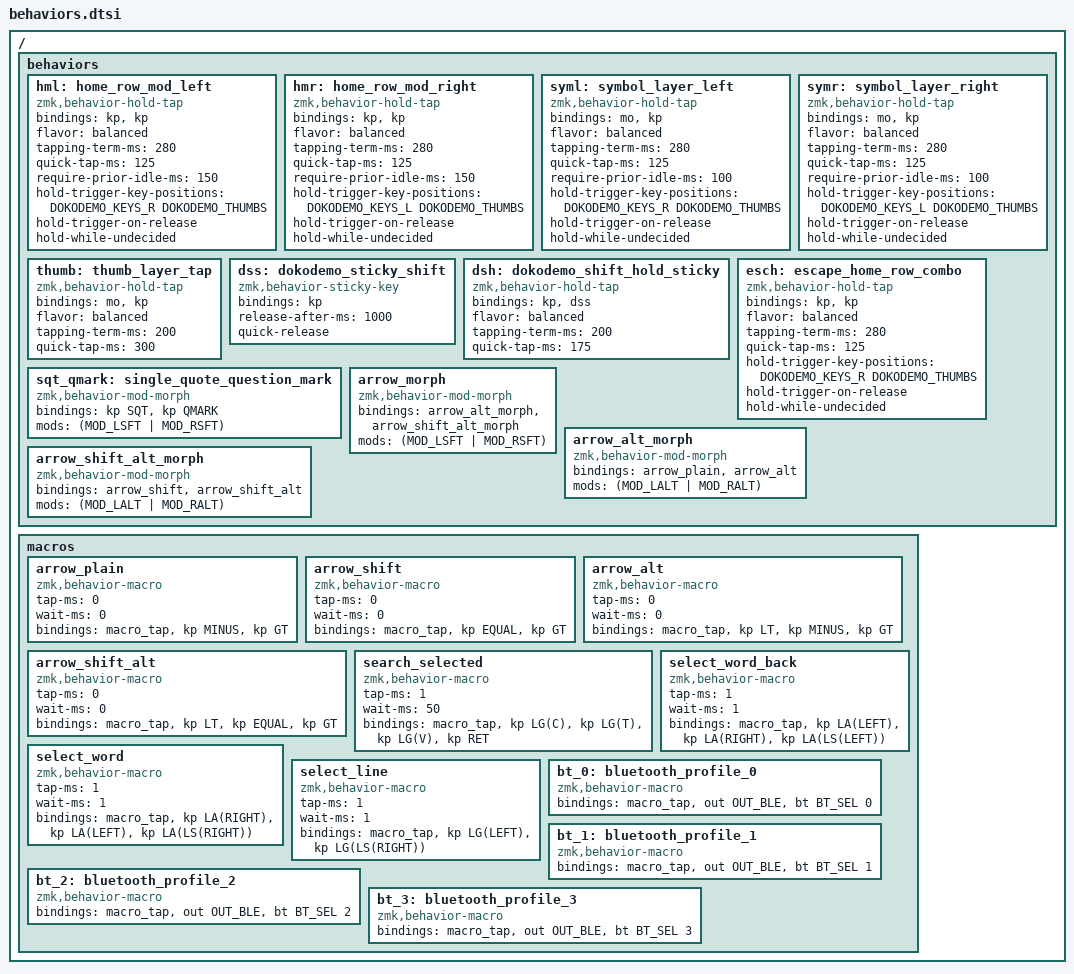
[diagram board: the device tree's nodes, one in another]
#include <behaviors.dtsi>
#include <dt-bindings/zmk/bt.h>
#include <dt-bindings/zmk/keys.h>
#include <dt-bindings/zmk/modifiers.h>
#include <dt-bindings/zmk/outputs.h>

#define DOKODEMO_KEYS_L 0 1 2 3 4 10 11 12 13 14 20 21 22 23 24
#define DOKODEMO_KEYS_R 5 6 7 8 9 15 16 17 18 19 25 26 27 28 29
#define DOKODEMO_THUMBS 30 31 32 33

/ {
    behaviors {
        // Go60-style bilateral home-row mods for the non-index fingers.
        hml: home_row_mod_left {
            compatible = "zmk,behavior-hold-tap";
            #binding-cells = <2>;
            bindings = <&kp>, <&kp>;
            flavor = "balanced";
            tapping-term-ms = <280>;
            quick-tap-ms = <125>;
            require-prior-idle-ms = <150>;
            hold-trigger-key-positions = <DOKODEMO_KEYS_R DOKODEMO_THUMBS>;
            hold-trigger-on-release;
            hold-while-undecided;
        };

        hmr: home_row_mod_right {
            compatible = "zmk,behavior-hold-tap";
            #binding-cells = <2>;
            bindings = <&kp>, <&kp>;
            flavor = "balanced";
            tapping-term-ms = <280>;
            quick-tap-ms = <125>;
            require-prior-idle-ms = <150>;
            hold-trigger-key-positions = <DOKODEMO_KEYS_L DOKODEMO_THUMBS>;
            hold-trigger-on-release;
            hold-while-undecided;
        };

        // The index home keys hold the Symbol layer instead of a modifier.
        syml: symbol_layer_left {
            compatible = "zmk,behavior-hold-tap";
            #binding-cells = <2>;
            bindings = <&mo>, <&kp>;
            flavor = "balanced";
            tapping-term-ms = <280>;
            quick-tap-ms = <125>;
            require-prior-idle-ms = <100>;
            hold-trigger-key-positions = <DOKODEMO_KEYS_R DOKODEMO_THUMBS>;
            hold-trigger-on-release;
            hold-while-undecided;
        };

        symr: symbol_layer_right {
            compatible = "zmk,behavior-hold-tap";
            #binding-cells = <2>;
            bindings = <&mo>, <&kp>;
            flavor = "balanced";
            tapping-term-ms = <280>;
            quick-tap-ms = <125>;
            require-prior-idle-ms = <100>;
            hold-trigger-key-positions = <DOKODEMO_KEYS_L DOKODEMO_THUMBS>;
            hold-trigger-on-release;
            hold-while-undecided;
        };

        // Go60's balanced layer-tap behavior for Backspace/Cursor and Space/Num.
        thumb: thumb_layer_tap {
            compatible = "zmk,behavior-hold-tap";
            #binding-cells = <2>;
            bindings = <&mo>, <&kp>;
            flavor = "balanced";
            tapping-term-ms = <200>;
            quick-tap-ms = <300>;
        };

        // Hold for Shift; tap for one-shot Shift on the next resolved keycode.
        dss: dokodemo_sticky_shift {
            compatible = "zmk,behavior-sticky-key";
            #binding-cells = <1>;
            bindings = <&kp>;
            release-after-ms = <1000>;
            quick-release;
        };

        dsh: dokodemo_shift_hold_sticky {
            compatible = "zmk,behavior-hold-tap";
            #binding-cells = <2>;
            bindings = <&kp>, <&dss>;
            flavor = "balanced";
            tapping-term-ms = <200>;
            quick-tap-ms = <175>;
        };

        // Tap the A+S combo for Escape; hold it with the other hand for Ctrl+Alt.
        esch: escape_home_row_combo {
            compatible = "zmk,behavior-hold-tap";
            #binding-cells = <2>;
            bindings = <&kp>, <&kp>;
            flavor = "balanced";
            tapping-term-ms = <280>;
            quick-tap-ms = <125>;
            hold-trigger-key-positions = <DOKODEMO_KEYS_R DOKODEMO_THUMBS>;
            hold-trigger-on-release;
            hold-while-undecided;
        };

        // A single quote on tap, but a question mark when either Shift is held.
        sqt_qmark: single_quote_question_mark {
            compatible = "zmk,behavior-mod-morph";
            #binding-cells = <0>;
            bindings = <&kp SQT>, <&kp QMARK>;
            mods = <(MOD_LSFT | MOD_RSFT)>;
        };

        // Shift selects => instead of ->; Alt adds a leading <.
        arrow_morph: arrow_morph {
            compatible = "zmk,behavior-mod-morph";
            #binding-cells = <0>;
            bindings = <&arrow_alt_morph>, <&arrow_shift_alt_morph>;
            mods = <(MOD_LSFT | MOD_RSFT)>;
        };

        arrow_alt_morph: arrow_alt_morph {
            compatible = "zmk,behavior-mod-morph";
            #binding-cells = <0>;
            bindings = <&arrow_plain>, <&arrow_alt>;
            mods = <(MOD_LALT | MOD_RALT)>;
        };

        arrow_shift_alt_morph: arrow_shift_alt_morph {
            compatible = "zmk,behavior-mod-morph";
            #binding-cells = <0>;
            bindings = <&arrow_shift>, <&arrow_shift_alt>;
            mods = <(MOD_LALT | MOD_RALT)>;
        };
    };

    macros {
        arrow_plain: arrow_plain {
            compatible = "zmk,behavior-macro";
            #binding-cells = <0>;
            tap-ms = <0>;
            wait-ms = <0>;
            bindings = <&macro_tap>, <&kp MINUS>, <&kp GT>;
        };

        arrow_shift: arrow_shift {
            compatible = "zmk,behavior-macro";
            #binding-cells = <0>;
            tap-ms = <0>;
            wait-ms = <0>;
            bindings = <&macro_tap>, <&kp EQUAL>, <&kp GT>;
        };

        arrow_alt: arrow_alt {
            compatible = "zmk,behavior-macro";
            #binding-cells = <0>;
            tap-ms = <0>;
            wait-ms = <0>;
            bindings = <&macro_tap>, <&kp LT>, <&kp MINUS>, <&kp GT>;
        };

        arrow_shift_alt: arrow_shift_alt {
            compatible = "zmk,behavior-macro";
            #binding-cells = <0>;
            tap-ms = <0>;
            wait-ms = <0>;
            bindings = <&macro_tap>, <&kp LT>, <&kp EQUAL>, <&kp GT>;
        };

        search_selected: search_selected {
            compatible = "zmk,behavior-macro";
            #binding-cells = <0>;
            tap-ms = <1>;
            wait-ms = <50>;
            bindings = <&macro_tap>, <&kp LG(C)>, <&kp LG(T)>, <&kp LG(V)>, <&kp RET>;
        };

        select_word_back: select_word_back {
            compatible = "zmk,behavior-macro";
            #binding-cells = <0>;
            tap-ms = <1>;
            wait-ms = <1>;
            bindings = <&macro_tap>, <&kp LA(LEFT)>, <&kp LA(RIGHT)>, <&kp LA(LS(LEFT))>;
        };

        select_word: select_word {
            compatible = "zmk,behavior-macro";
            #binding-cells = <0>;
            tap-ms = <1>;
            wait-ms = <1>;
            bindings = <&macro_tap>, <&kp LA(RIGHT)>, <&kp LA(LEFT)>, <&kp LA(LS(RIGHT))>;
        };

        select_line: select_line {
            compatible = "zmk,behavior-macro";
            #binding-cells = <0>;
            tap-ms = <1>;
            wait-ms = <1>;
            bindings = <&macro_tap>, <&kp LG(LEFT)>, <&kp LG(LS(RIGHT))>;
        };

        // Selecting a profile also switches the keyboard to BLE output.
        bt_0: bluetooth_profile_0 {
            compatible = "zmk,behavior-macro";
            #binding-cells = <0>;
            bindings = <&macro_tap>, <&out OUT_BLE>, <&bt BT_SEL 0>;
        };

        bt_1: bluetooth_profile_1 {
            compatible = "zmk,behavior-macro";
            #binding-cells = <0>;
            bindings = <&macro_tap>, <&out OUT_BLE>, <&bt BT_SEL 1>;
        };

        bt_2: bluetooth_profile_2 {
            compatible = "zmk,behavior-macro";
            #binding-cells = <0>;
            bindings = <&macro_tap>, <&out OUT_BLE>, <&bt BT_SEL 2>;
        };

        bt_3: bluetooth_profile_3 {
            compatible = "zmk,behavior-macro";
            #binding-cells = <0>;
            bindings = <&macro_tap>, <&out OUT_BLE>, <&bt BT_SEL 3>;
        };
    };
};
